# FSS0_FSS0_FSAS_GENREGS_0FC10000h register map
Vendor: Texas Instruments
Peripheral module from a debugger description file (folder AM275x).
Registers are 32-bit, access not given, reset 0x0 unless marked. A register's access mark holds for its fields unless they carry their own. Offsets are as the file gives them; lines under a group give offsets from that group; [hi:lo] are bit positions; {n}, {i} and the like mark numbered series; 'fields as' and 'values as' point back to an identical list; <NAME> marks a mode.

## FSS0_fsas_genregs
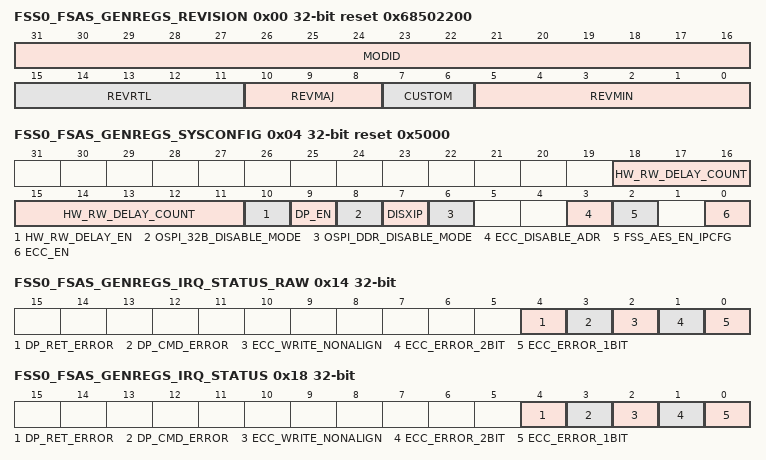
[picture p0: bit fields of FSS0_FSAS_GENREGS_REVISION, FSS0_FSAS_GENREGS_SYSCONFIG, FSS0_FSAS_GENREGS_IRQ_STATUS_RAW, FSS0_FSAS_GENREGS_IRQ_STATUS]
0x00 FSS0_FSAS_GENREGS_REVISION ro reset 0x68502200 — IP Revision Identifier (X.Y.R) Used by software to track features, bugs, and compatibility
  [31:16] MODID — Module ID field Reset Source: vbus_mod_g_rst_n
  [15:11] REVRTL — RTL revision. Will vary depending on release. Reset Source: vbus_mod_g_rst_n
  [10:8] REVMAJ — Major revision Reset Source: vbus_mod_g_rst_n
  [7:6] CUSTOM — Custom Reset Source: vbus_mod_g_rst_n
  [5:0] REVMIN — Minor revision Reset Source: vbus_mod_g_rst_n
0x04 FSS0_FSAS_GENREGS_SYSCONFIG access per field reset 0x5000 — Controls various parameters of the cotroller state.
  [18:11] HW_RW_DELAY_COUNT rw — Delay for switching between reads and writes Reset Source: vbus_mod_g_rst_n
  [10] HW_RW_DELAY_EN rw — Enable delay when switching between reads and writes to avoid read-write collision for sensitive logic. Reset Source: vbus_mod_g_rst_n
  [9] DP_EN rw — 0 Safety double pumping disabled. 1 Safety double pumping enabled Reset Source: vbus_mod_g_rst_n
  [8] OSPI_32B_DISABLE_MODE rw — 0 OSPI 32bit mode enabled. 1 OSPI 32bit mode disabled Reset Source: vbus_mod_g_rst_n
  [7] DISXIP rw — This field is used to disable XIP prefetching. 0 XIP Prefetch Enabled. 1 XIP prefetch disabled Please note that this is referring to prefetching feature that is useful for linear accesses associated with XIP. This is NOT referring to XIP features implemented in flash Controller or memory device. Reset Source: vbus_mod_g_rst_n
  [6] OSPI_DDR_DISABLE_MODE rw — 0 OSPI DDR mode enabled. 1 OSPI DDR mode disabled Reset Source: vbus_mod_g_rst_n
  [3] ECC_DISABLE_ADR rw — 0 Block address within ECC calculation, 1 Block address not within ECC calculation Reset Source: vbus_mod_g_rst_n
  [2] FSS_AES_EN_IPCFG ro — 1 select security, 0 disable security Reset Source: vbus_mod_g_rst_n
  [0] ECC_EN rw — 0 ECC disabled. 1 ECC enabled Reset Source: vbus_mod_g_rst_n
0x10 FSS0_FSAS_GENREGS_IRQ_EOI wo — The End of Interrupt (EOI) Register allows the CPU to acknowledge completion of fsas_ecc_intr_err_req pulse interrupt. When this register is written to 1'b0, INTD logic used for converting fsas_ecc_intr_err_pend level interrupt to pulse will be re-armed. That is, if interrupt sources remain after writing this register to 1'b0, another pulse interrupt will be triggered by INTD. Conversely, if this register is not written to 1'b0 after fsas_ecc_intr_err_req pulse interrupt is received, then another pulse interrupt will not be received as INTD has not been re-armed. This register will be reset one cycle after it has been written to. Please note that the reason for writing 1'b0 is because there is only one interrupt (no interrupt aggregation) associated with this EOI and the INTD vector associated with this interrupt is 1'b0.
  [0] EOI_VECTOR — Write 1'b0 to acknowledge fsas_ecc_intr_err_req pulse interrupt. Reset Source: vbus_mod_g_rst_n
0x14 FSS0_FSAS_GENREGS_IRQ_STATUS_RAW — The IRQ_STATUS_RAW register allows the interrupt sources associated with each bit in this register to be manually set when writing a 1 to a specific bit. This register corresponds to fsas_ecc_intr_err_pend (level) and fsas_ecc_intr_err_req (pulse) interrupt outputs. Write 0: No action Write 1: Set event Read 0: No event pending Read 1: Event pending
  [4] DP_RET_ERROR — Safety double pumping read return error Reset Source: vbus_mod_g_rst_n (access R/W1TS)
  [3] DP_CMD_ERROR — Safety double pumping command error Reset Source: vbus_mod_g_rst_n (access R/W1TS)
  [2] ECC_WRITE_NONALIGN — Write is not aligned to 32B boundary or not a multiple of 32B Reset Source: vbus_mod_g_rst_n (access R/W1TS)
  [1] ECC_ERROR_2BIT — An ECC error occurred on 2 bits and was not correctable Reset Source: vbus_mod_g_rst_n (access R/W1TS)
  [0] ECC_ERROR_1BIT — An ECC error occurred on only 1 bit and was corrected Reset Source: vbus_mod_g_rst_n (access R/W1TS)
0x18 FSS0_FSAS_GENREGS_IRQ_STATUS — The IRQ_STATUS register allows the interrupt sources associated with each bit in this register to be manually cleared when writing a 1 to a specific bit. This register corresponds to fsas_ecc_intr_err_pend (level) and fsas_ecc_intr_err_req (pulse) interrupt outputs. Write 0: No action Write 1: Clear event Read 0: No event pending Read 1: Event pending
  [4] DP_RET_ERROR — Safety double pumping read return error Reset Source: vbus_mod_g_rst_n (access R/W1TC)
  [3] DP_CMD_ERROR — Safety double pumping command error Reset Source: vbus_mod_g_rst_n (access R/W1TC)
  [2] ECC_WRITE_NONALIGN — Write is not aligned to 32B boundary or not a multiple of 32B Reset Source: vbus_mod_g_rst_n (access R/W1TC)
  [1] ECC_ERROR_2BIT — An ECC error on 2 bits. Not correctable Reset Source: vbus_mod_g_rst_n (access R/W1TC)
  [0] ECC_ERROR_1BIT — ECC error on 1 bits. corrected Reset Source: vbus_mod_g_rst_n (access R/W1TC)
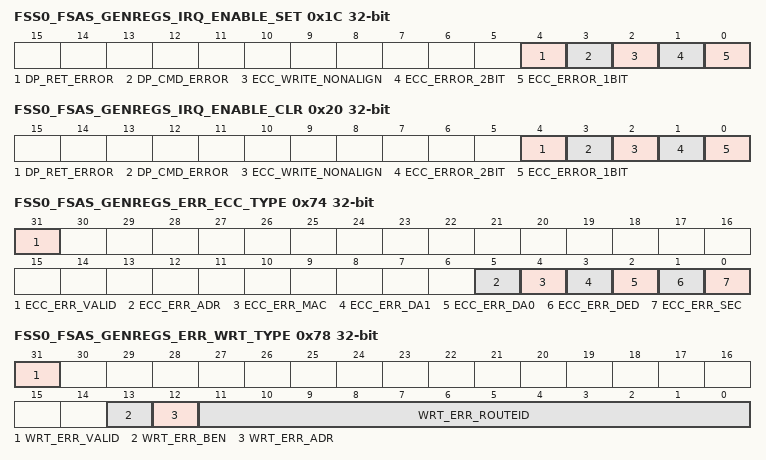
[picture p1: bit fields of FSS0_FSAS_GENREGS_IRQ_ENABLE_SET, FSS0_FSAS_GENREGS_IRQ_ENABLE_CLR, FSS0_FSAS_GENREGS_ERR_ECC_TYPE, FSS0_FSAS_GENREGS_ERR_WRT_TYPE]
0x1C FSS0_FSAS_GENREGS_IRQ_ENABLE_SET — The IRQ_ENABLE_SET register allows the interrupt sources associated with each bit in this register to be manually enabled when writing a 1 to a specific bit. This register corresponds to fsas_ecc_intr_err_pend (level) and fsas_ecc_intr_err_req (pulse) interrupt outputs. Write 0: No action Write 1: Enable event Read 0: Event is disabled Read 1: Event is enabled
  [4] DP_RET_ERROR — Safety double pumping read return error Reset Source: vbus_mod_g_rst_n (access R/W1TS)
  [3] DP_CMD_ERROR — Safety double pumping command error Reset Source: vbus_mod_g_rst_n (access R/W1TS)
  [2] ECC_WRITE_NONALIGN — Write is not aligned to 32B boundary or not a multiple of 32B Reset Source: vbus_mod_g_rst_n (access R/W1TS)
  [1] ECC_ERROR_2BIT — ECC error on 2 bits. Not correctable Reset Source: vbus_mod_g_rst_n (access R/W1TS)
  [0] ECC_ERROR_1BIT — ECC error on 1 bits. corrected Reset Source: vbus_mod_g_rst_n (access R/W1TS)
0x20 FSS0_FSAS_GENREGS_IRQ_ENABLE_CLR — The IRQ_ENABLE_CLR register allows the interrupt sources associated with each bit in this register to be manually disabled when writing a 1 to a specific bit. This register corresponds to fsas_ecc_intr_err_pend (level) and fsas_ecc_intr_err_req (pulse) interrupt outputs. Write 0: No action Write 1: Disable event Read 0: Event is disabled Read 1: Event is enabled
  [4] DP_RET_ERROR — Safety double pumping read return error Reset Source: vbus_mod_g_rst_n (access R/W1TC)
  [3] DP_CMD_ERROR — Safety double pumping command error Reset Source: vbus_mod_g_rst_n (access R/W1TC)
  [2] ECC_WRITE_NONALIGN — Write is not aligned to 32B boundary or not a multiple of 32B Reset Source: vbus_mod_g_rst_n (access R/W1TC)
  [1] ECC_ERROR_2BIT — ECC error on 2 bits. Not correctable Reset Source: vbus_mod_g_rst_n (access R/W1TC)
  [0] ECC_ERROR_1BIT — ECC error on 1 bits. corrected Reset Source: vbus_mod_g_rst_n (access R/W1TC)
0x30 FSS0_FSAS_GENREGS_ECC_REGCTRL_ECC_RGSTRT_j rw — This defines the start of the ECC region in 4KBytes steps.
  [19:0] R_START — This defines the start of the ECC region in 4KBytes steps. Address start = {start[19:0], 0x000}0x0 means the start is 0x0000_0000 0x1 means the start is 0x0000_10000xA means the start is 0x0000_A000Note the offset + size should be <= 4GBytes, wrap around is not supported. Reset Source: vbus_mod_g_rst_n
0x34 FSS0_FSAS_GENREGS_ECC_REGCTRL_ECC_RGSIZ_j rw — This defines the size of the ECC region in 4KBytes steps.
  [19:0] R_SIZE — This defines the size of the ECC region in 4KBytes steps0x0 means the size is zero and disabled 0x1 means the size is 4KBytes0xA means the size is 40KBytes0xF_FFFF means the size is 4GBytesNote the offset + size should be <= 4GBytes, wrap around is not supported. Reset Source: vbus_mod_g_rst_n
0x70 FSS0_FSAS_GENREGS_ERR_ECC_BLOCK_ADR ro — The ERR_ECC_BLOCK_ADR register holds the current top of stack ECC error block address, this is only valid when the ecc_err_valid is set
  [31:5] ECC_ERROR_BLOCK_ADDR — ECC 32 byte aligned block address Reset Source: vbus_mod_g_rst_n
0x74 FSS0_FSAS_GENREGS_ERR_ECC_TYPE — The ERR_ECC_TYPE register holds the current top of stack ECC error info, this is only valid when the ecc_err_valid is set
  [31] ECC_ERR_VALID — When set indicates that there is valid ECC error information available, Writing a one to this register will pop the top of the stack Reset Source: vbus_mod_g_rst_n (access R/W1TC)
  [5] ECC_ERR_ADR ro — When set indicates that there was a single error detected within the address field. Bits 0 and 1 in this register indicate whether it is single or double error. Reset Source: vbus_mod_g_rst_n
  [4] ECC_ERR_MAC ro — When set indicates that there was a single error detected within the MAC field. Bits 0 and 1 in this register indicate whether it is single or double error. Reset Source: vbus_mod_g_rst_n
  [3] ECC_ERR_DA1 ro — When set indicates that there was a single error detected within the High Data word, which is bits 127 through 64 of the data word. Bits 0 and 1 in this register indicate whether it is single or double error. Reset Source: vbus_mod_g_rst_n
  [2] ECC_ERR_DA0 ro — When set indicates that there was a single error detected within the Low Data word, which is bits 63 through 0 of the data word. Bits 0 and 1 in this register indicate whether it is single or double error. Reset Source: vbus_mod_g_rst_n
  [1] ECC_ERR_DED ro — When set indicates that there was a double error detected for the block Reset Source: vbus_mod_g_rst_n
  [0] ECC_ERR_SEC ro — When set indicates that there was a single error detected for the block. The fields that had single error are reported by bits 2 through 5 in this register. It is possible that single error is reported in multiple fields since the ECCM inputs are partitioned into four partitions and ECC code is separate for each partition. It is also possible that none of the fields report single error even though ecc_err_sec bit is set. This can happen if single bit error occurred on the ECC code. Reset Source: vbus_mod_g_rst_n
0x78 FSS0_FSAS_GENREGS_ERR_WRT_TYPE — The ERR_WRT_TYPE register holds the current top of stack write error info. this is only valid when the wrt_err_valid is set
  [31] WRT_ERR_VALID — When set indicates that there is valid write error information available, Writing a one to this register will pop the top of the stack Reset Source: vbus_mod_g_rst_n (access R/W1TC)
  [13] WRT_ERR_BEN ro — When set indicates that there was a write error due to a non-contiguous byte enables or because write byte count was not 32-byte multiple. Please note that this bit will always be set when wrt_err_valid bit is set. There is no write error if byte count is 32-byte multiple and if byte-enables are all set. Reset Source: vbus_mod_g_rst_n
  [12] WRT_ERR_ADR ro — When set indicates that there was a write error due to a non-aligned address. Please note that this bit can only be set if address was 16-byte multiple but not 32-byte multiple. For example, an address of 0x10 or 0x30 for writes will cause this bit to get set. Reset Source: vbus_mod_g_rst_n
  [11:0] WRT_ERR_ROUTEID ro — Indicates the Route ID for the Initiator that caused the write error Reset Source: vbus_mod_g_rst_n
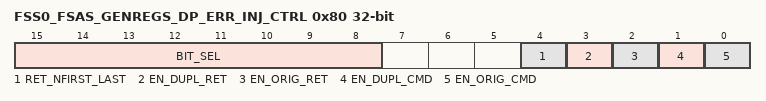
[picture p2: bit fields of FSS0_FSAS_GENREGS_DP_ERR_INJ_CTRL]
0x80 FSS0_FSAS_GENREGS_DP_ERR_INJ_CTRL rw — This register is used to setup double pumping error injection. Only one error injection enable field has to be set in this register at a given time. After error injection is enabled, a read must be issued to a valid flash address in order to trigger the error. Once triggered, the error will be reported using IRQ.STATUS register dp_cmd_err/dp_ret_err fields and corresponding interrupt fsas_ecc_intr_err_pend/fsas_ecc_intr_err_req will be generated if enabled.
  [15:8] BIT_SEL — Bit select for injecting error on command or read return fields. For command error, only 0 through 47 are valid values for bit select. For read return error, only 0 through 166 are valid values for bit select. Reset Source: vbus_mod_g_rst_n
  [4] RET_NFIRST_LAST — 1'b0 - Inject on first read return phase, 1'b1 - Inject on last read return phase Reset Source: vbus_mod_g_rst_n
  [3] EN_DUPL_RET — Enable error injection on duplicate read return fields. Reset Source: vbus_mod_g_rst_n
  [2] EN_ORIG_RET — Enable error injection on original read return fields. Reset Source: vbus_mod_g_rst_n
  [1] EN_DUPL_CMD — Enable error injection on duplicate command fields. Reset Source: vbus_mod_g_rst_n
  [0] EN_ORIG_CMD — Enable error injection on original command fields. Reset Source: vbus_mod_g_rst_n
